AUTOSAR XML (schema 4-0-3)
package /ComponentTypes
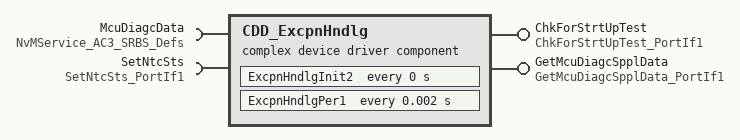
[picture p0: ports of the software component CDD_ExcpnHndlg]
  complex device driver sw component type CDD_ExcpnHndlg
    provide port ChkForStrtUpTest: server-com-spec{operation=Oper, queue-length=1}, provided-interface=ChkForStrtUpTest_PortIf1
    provide port GetMcuDiagcSpplData: server-com-spec{operation=Oper, queue-length=1}, provided-interface=GetMcuDiagcSpplData_PortIf1
    require port McuDiagcData: required-interface=NvMService_AC3_SRBS_Defs
    require port SetNtcSts: required-interface=SetNtcSts_PortIf1
    behavior CDD_ExcpnHndlg_InternalBehavior
      ar-typed-per-instance-memorys:
        data McuDiagcData: sw-calibration-access=READ-ONLY, type=Ary1D_u32_4
      operation invoked event OIT_ChkForStrtUpTest_Oper_ChkForStrtUpTest_Oper: start-on-event=ChkForStrtUpTest_Oper, operation=ChkForStrtUpTest.Oper
      timing event CDD_ExcpnHndlg_InitEvent: start-on-event=ExcpnHndlgInit2, period=0
      timing event TMT_ExcpnHndlgPer1: start-on-event=ExcpnHndlgPer1, period=0.002
      operation invoked event OIT_GetMcuDiagcSpplData_Oper_GetMcuDiagcSpplData_Oper: start-on-event=GetMcuDiagcSpplData_Oper, operation=GetMcuDiagcSpplData.Oper
      4 x runnable:
        ChkForStrtUpTest_Oper
        ExcpnHndlgInit2
          sync call SC_McuDiagcData_SetRamBlockStatus: operation=McuDiagcData.SetRamBlockStatus, timeout=0
          sync call SC_SetNtcSts_Oper: operation=SetNtcSts.Oper, timeout=0
        ExcpnHndlgPer1
          sync call SC_SetNtcSts_Oper: operation=SetNtcSts.Oper, timeout=0
        GetMcuDiagcSpplData_Oper
      swc service dependency NvmMcuDiagcData
        assigned-datas:
          role=ramBlock, used-data-element=McuDiagcData
          role=defaultValue, used-parameter-element=McuDiagcDataDft
        assigned-ports:
          port-prototype=McuDiagcData, role=NvMService_AC3_SRBS_Defs
          port-prototype=McuDiagcData, role=NvMService_AC3_SRBS_Defs
        service-needs:
          nv block needs NvmMcuDiagcData: n-data-sets=0, readonly=false, reliability=ERROR-DETECTION, resistant-to-changed-sw=true, restore-at-start=true, store-at-shutdown=true, write-only-once=false, writing-frequency=0, writing-priority=LOW
      shared-parameters:
        parameter data prototype McuDiagcDataDft: sw-calibration-access=READ-WRITE, type=Ary1D_u32_4, init-value=[0, 0, 0, 0]
  swc implementation CDD_ExcpnHndlg_Implementation: behavior=CDD_ExcpnHndlg_InternalBehavior
    code-descriptors:
      code Default: artifact-descriptors=autosar-engineering-object={short-label=Default, category=SWSRC}
